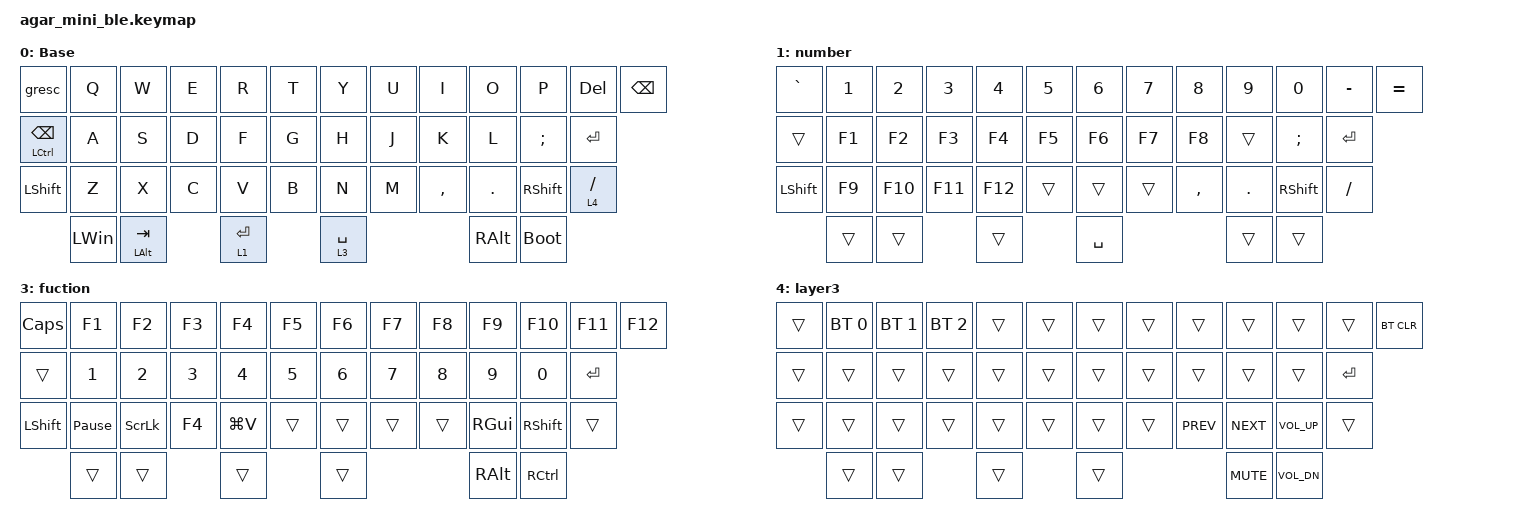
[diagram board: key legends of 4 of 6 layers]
/*
 * Copyright (c) 2021 The ZMK Contributors
 *
 * SPDX-License-Identifier: MIT
 */

#include "./boards/shields/klink_kbd/common.keymap"
#include <behaviors.dtsi>
#include <dt-bindings/zmk/bt.h>
#include <dt-bindings/zmk/keys.h>
#include <dt-bindings/zmk/pointing.h>

/ {
    combos {
        compatible = "zmk,combos";

        exclamation {
            bindings = <&kp EXCLAMATION>;
            key-positions = <1 0>;
            layers = <0>;
        };

        at {
            bindings = <&kp AT_SIGN>;
            key-positions = <1 2>;
            layers = <0>;
        };

        hash {
            bindings = <&kp HASH>;
            key-positions = <2 3>;
            layers = <0>;
        };

        dollor {
            bindings = <&kp DOLLAR>;
            key-positions = <3 4>;
            layers = <0>;
        };

        per {
            bindings = <&kp PERCENT>;
            key-positions = <4 5>;
            layers = <0>;
        };

        caret {
            bindings = <&kp CARET>;
            key-positions = <5 6>;
            layers = <0>;
        };

        amps {
            bindings = <&kp AMPERSAND>;
            key-positions = <6 7>;
            layers = <0>;
        };

        astrk {
            bindings = <&kp ASTERISK>;
            key-positions = <8 7>;
            layers = <0>;
        };

        lpar {
            bindings = <&kp LEFT_PARENTHESIS>;
            key-positions = <9 8>;
            layers = <0>;
        };

        rpar {
            bindings = <&kp RIGHT_PARENTHESIS>;
            key-positions = <10 9>;
            layers = <0>;
        };

        minus {
            bindings = <&kp MINUS>;
            key-positions = <11 10>;
            layers = <0>;
        };

        equ {
            bindings = <&kp EQUAL>;
            key-positions = <11 12>;
            layers = <0>;
        };

        excl {
            bindings = <&kp EXCLAMATION>;
            key-positions = <17 16>;
            layers = <0>;
        };

        qmark {
            bindings = <&kp QUESTION>;
            key-positions = <21 20>;
            layers = <0>;
        };

        sqt {
            bindings = <&kp SQT>;
            key-positions = <24 23>;
            layers = <0>;
        };

        capsword {
            bindings = <&caps_word>;
            key-positions = <32 31>;
        };
    };

    behaviors {
        LT_tap: LT_tap {
            compatible = "zmk,behavior-hold-tap";
            label = "LT_TAP";
            bindings = <&mo>, <&kp>;

            #binding-cells = <2>;
            tapping-term-ms = <200>;
            quick-tap-ms = <200>;
            require-prior-idle-ms = <50>;
            flavor = "tap-preferred";
            retro-tap;
        };

        MT_tap: MT_tap {
            compatible = "zmk,behavior-hold-tap";
            label = "MT_TAP";
            bindings = <&kp>, <&kp>;

            #binding-cells = <2>;
            tapping-term-ms = <200>;
            quick-tap-ms = <200>;
            flavor = "tap-preferred";
            retro-tap;
        };
    };

    keymap {
        compatible = "zmk,keymap";

        Base {
            bindings = <
&gresc               &kp Q         &kp W             &kp E  &kp R            &kp T  &kp Y            &kp U  &kp I      &kp O          &kp P        &kp DELETE   &kp BSPC
&mt LCTRL BACKSPACE  &kp A         &kp S             &kp D  &kp F            &kp G  &kp H            &kp J  &kp K      &kp L          &kp SEMI     &kp RET
&kp LSHFT            &kp Z         &kp X             &kp C  &kp V            &kp B  &kp N            &kp M  &kp COMMA  &kp DOT        &kp RSHIFT   &lt 4 SLASH
                     &kp LEFT_WIN  &MT_tap LALT TAB         &LT_tap 1 ENTER         &LT_tap 3 SPACE                    &kp RIGHT_ALT  &bootloader
            >;
        };

        number {
            bindings = <
&kp GRAVE  &kp N1  &kp N2   &kp N3   &kp N4   &kp N5  &kp N6     &kp N7  &kp N8     &kp N9   &kp N0     &kp MINUS  &kp EQUAL
&trans     &kp F1  &kp F2   &kp F3   &kp F4   &kp F5  &kp F6     &kp F7  &kp F8     &trans   &kp SEMI   &kp ENTER
&kp LSHFT  &kp F9  &kp F10  &kp F11  &kp F12  &trans  &trans     &trans  &kp COMMA  &kp DOT  &kp RSHFT  &kp FSLH
           &trans  &trans            &trans           &kp SPACE                     &trans   &trans
            >;
        };

        layer_5 {
            bindings = <
&trans          &trans  &trans  &trans  &trans  &trans  &trans  &trans    &kp UP    &trans     &trans           &trans  &trans
&trans          &trans  &trans  &trans  &trans  &trans  &trans  &kp LEFT  &kp DOWN  &kp RIGHT  &trans           &trans
&kp LEFT_SHIFT  &trans  &trans  &trans  &trans  &trans  &trans  &trans    &trans    &trans     &kp RIGHT_SHIFT  &trans
                &trans  &trans          &trans          &trans                      &trans     &trans                   &trans
            >;
        };

        fuction {
            bindings = <
&kp CAPSLOCK  &kp F1           &kp F2          &kp F3  &kp F4     &kp F5  &kp F6  &kp F7  &kp F8  &kp F9    &kp F10    &kp F11    &kp F12
&trans        &kp N1           &kp N2          &kp N3  &kp N4     &kp N5  &kp N6  &kp N7  &kp N8  &kp N9    &kp N0     &kp ENTER
&kp LSHFT     &kp PAUSE_BREAK  &kp SCROLLLOCK  &kp F4  &kp LG(V)  &trans  &trans  &trans  &trans  &kp RGUI  &kp RSHFT  &trans
              &trans           &trans                  &trans             &trans                  &kp RALT  &kp RCTRL
            >;
        };

        layer3 {
            bindings = <
&trans  &bt BT_SEL 0  &bt BT_SEL 1  &bt BT_SEL 2  &trans  &trans  &trans  &trans  &trans      &trans      &trans        &trans     &bt BT_CLR
&trans  &trans        &trans        &trans        &trans  &trans  &trans  &trans  &trans      &trans      &trans        &kp ENTER
&trans  &trans        &trans        &trans        &trans  &trans  &trans  &trans  &kp C_PREV  &kp C_NEXT  &kp C_VOL_UP  &trans
        &trans        &trans                      &trans          &trans                      &kp C_MUTE  &kp C_VOL_DN
            >;
        };

        layer_4 {
            bindings = <
&trans  &trans  &trans          &trans          &trans           &trans  &trans  &trans  &trans  &trans  &trans  &trans  &trans
&trans  &trans  &trans          &mmv MOVE_UP    &trans           &trans  &trans  &trans  &trans  &trans  &trans  &trans
&trans  &trans  &mmv MOVE_LEFT  &mmv MOVE_DOWN  &mmv MOVE_RIGHT  &trans  &trans  &trans  &trans  &trans  &trans  &trans
        &trans  &trans                          &trans                   &trans                  &trans  &trans          &trans
            >;
        };
    };
};
